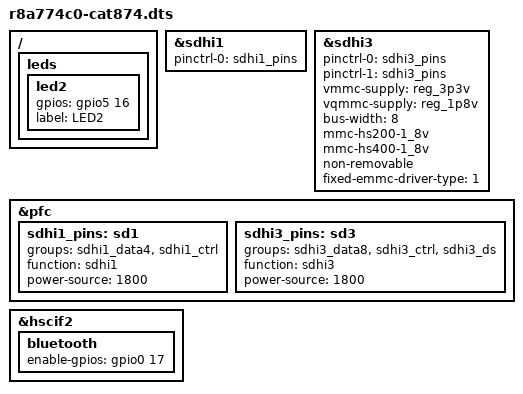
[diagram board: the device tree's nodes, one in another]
// SPDX-License-Identifier: GPL-2.0
/*
 * Device Tree Source for the Silicon Linux RZ/G2E 96board platform (CAT874)
 * Rev.[D,E]
 *
 * Copyright (C) 2019 Renesas Electronics Corp.
 */

/dts-v1/;
#include "r8a774c0.dtsi"
#define WIFI_PARENT_SDHI	sdhi1
#include "cat874-common.dtsi"

/ {
	leds {
		led2 {
			gpios = <&gpio5 16 GPIO_ACTIVE_HIGH>;
			label = "LED2";
		};
	};
};

&sdhi1 {
	pinctrl-0 = <&sdhi1_pins>;
	pinctrl-names = "default";
};

&sdhi3 {
	pinctrl-0 = <&sdhi3_pins>;
	pinctrl-1 = <&sdhi3_pins>;
	pinctrl-names = "default", "state_uhs";

	vmmc-supply = <&reg_3p3v>;
	vqmmc-supply = <&reg_1p8v>;
	bus-width = <8>;
	mmc-hs200-1_8v;
	mmc-hs400-1_8v;
	non-removable;
	fixed-emmc-driver-type = <1>;
	status = "okay";
};

&pfc {
	sdhi1_pins: sd1 {
		groups = "sdhi1_data4", "sdhi1_ctrl";
		function = "sdhi1";
		power-source = <1800>;
	};

	sdhi3_pins: sd3 {
		groups = "sdhi3_data8", "sdhi3_ctrl", "sdhi3_ds";
		function = "sdhi3";
		power-source = <1800>;
	};
};

&hscif2 {
	bluetooth {
		enable-gpios = <&gpio0 17 GPIO_ACTIVE_HIGH>;
	};
};
